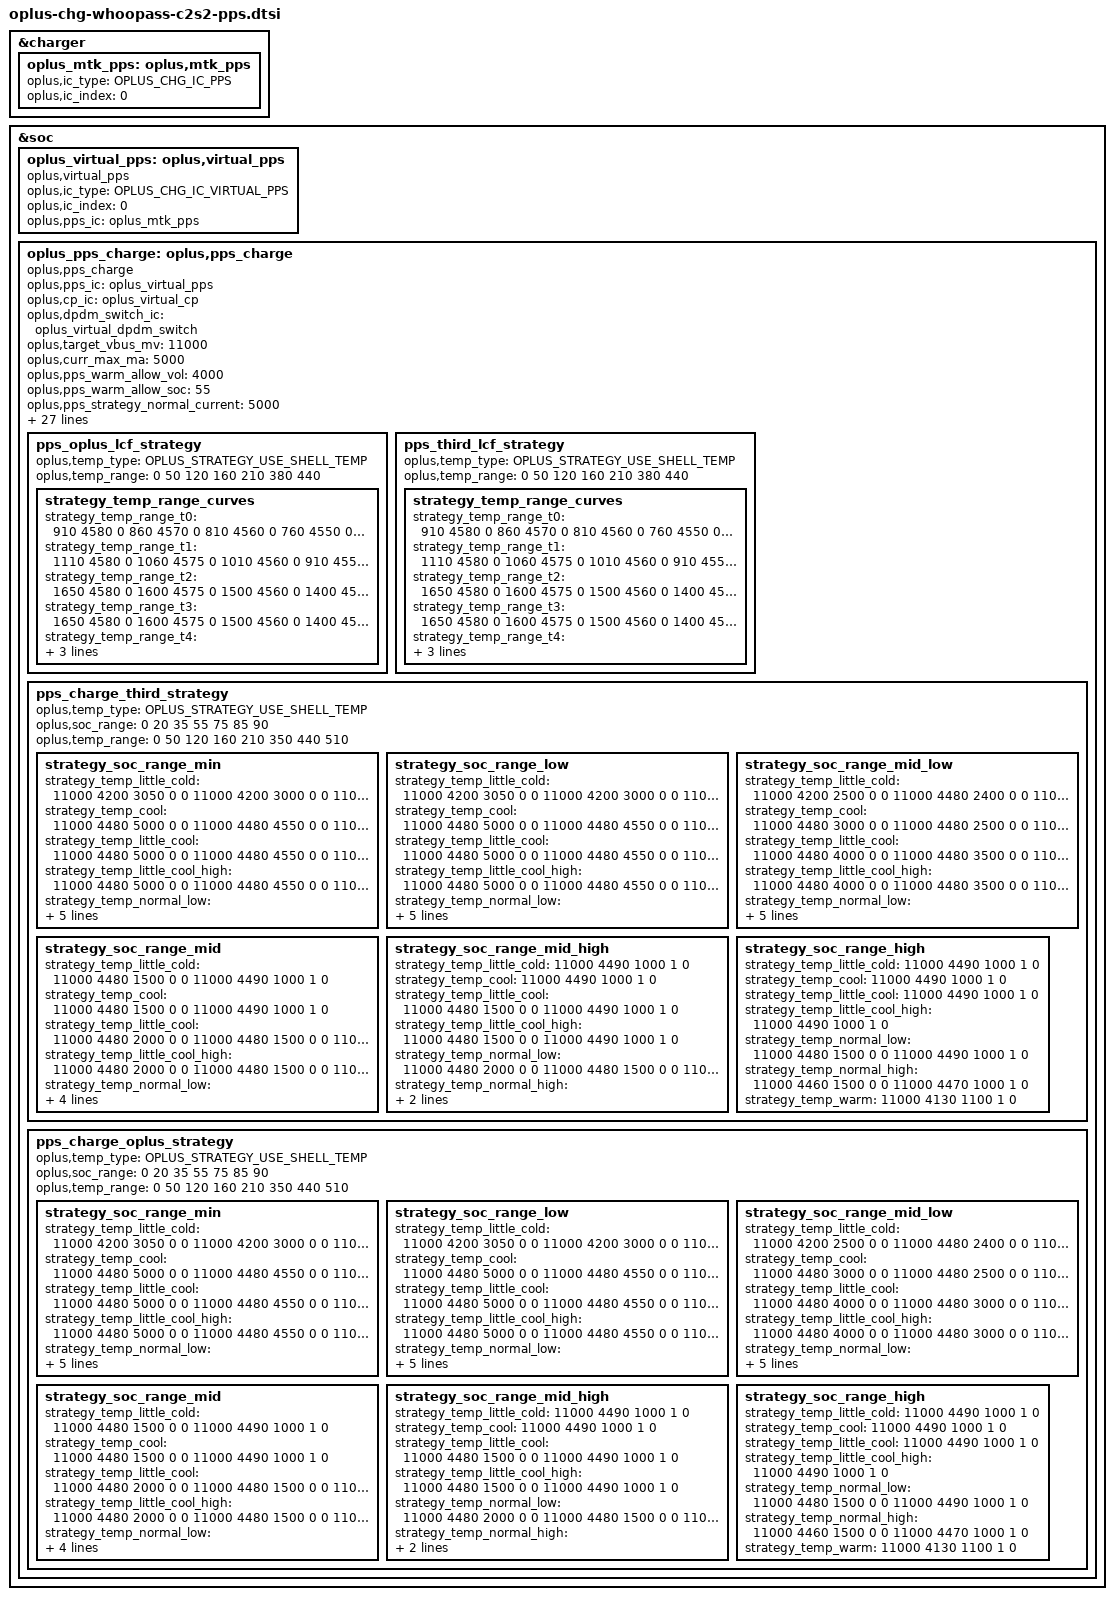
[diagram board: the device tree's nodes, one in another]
//ifdef OPLUS_FEATURE_CHG_BASIC
&charger {
	oplus_mtk_pps: oplus,mtk_pps {
		oplus,ic_type = <OPLUS_CHG_IC_PPS>;
		oplus,ic_index = <0>;
	};
};
&soc {
	oplus_virtual_pps: oplus,virtual_pps {
		compatible = "oplus,virtual_pps";

		oplus,ic_type = <OPLUS_CHG_IC_VIRTUAL_PPS>;
		oplus,ic_index = <0>;
		oplus,pps_ic = <&oplus_mtk_pps>;
	};
	oplus_pps_charge: oplus,pps_charge {
		compatible = "oplus,pps_charge";
		oplus,pps_ic = <&oplus_virtual_pps>;
		oplus,cp_ic = <&oplus_virtual_cp>;
		oplus,dpdm_switch_ic = <&oplus_virtual_dpdm_switch>;

		oplus,target_vbus_mv = <11000>;
		oplus,curr_max_ma = <5000>;

		oplus,pps_warm_allow_vol = <4000>;
		oplus,pps_warm_allow_soc = <55>;
		oplus,pps_strategy_normal_current = <5000>;
		oplus,pps_over_high_or_low_current = <3000>;
		oplus,pps_timeout_third = <15518>;
		oplus,pps_timeout_oplus = <15518>;
		oplus,pps_ibat_over_third = <11400>;
		oplus,pps_ibat_over_oplus = <11400>;
		oplus,pps_full_cool_sw_vbat = <4490>;
		oplus,pps_full_normal_sw_vbat = <4490>;
		oplus,pps_full_normal_hw_vbat = <4540>;
		oplus,pps_full_ffc_vbat = <4540>;
		oplus,pps_full_warm_vbat = <4130>;
		oplus,pps_full_cool_sw_vbat_third = <4490>;
		oplus,pps_full_normal_sw_vbat_third= <4490>;
		oplus,pps_full_normal_hw_vbat_third = <4540>;
		oplus,pps_current_change_timeout = <100>;
		oplus,curve_strategy_name = "pps_ufcs_curve_v2";
		oplus,pps_strategy_batt_high_temp = <410 420 430 400 410 420>;
		oplus,pps_strategy_high_current = <5000 4000 3000 5000 4000 3000>;
		oplus,pps_little_cool_high_temp = <210>;
		oplus,pps_charge_strategy_soc = <0 20 35 55 75 85 90>;
		oplus,pps_charge_strategy_temp = <0 50 120 160 350 440 510>;

		oplus,plc_strategy-data = <&cp_2t1_simple_strategy>;
		oplus,plc_strategy-names = "default";

		pps_oplus_lcf_strategy {
			oplus,temp_type = <OPLUS_STRATEGY_USE_SHELL_TEMP>;
			oplus,temp_range = <0 50 120 160 210 380 440>;

			strategy_temp_range_curves {
				strategy_temp_range_t0 =	<910 4580 0
								 860 4570 0
								 810 4560 0
								 760 4550 0
								 710 4540 1>;
				strategy_temp_range_t1 =	<1110 4580 0
								 1060 4575 0
								 1010 4560 0
								 910 4550 0
								 810 4540 1>;
				strategy_temp_range_t2 =	<1650 4580 0
								 1600 4575 0
								 1500 4560 0
								 1400 4550 0
								 1250 4540 1>;
				strategy_temp_range_t3 =	<1650 4580 0
								 1600 4575 0
								 1500 4560 0
								 1400 4550 0
								 1250 4540 1>;
				strategy_temp_range_t4 =	<2980 4570 0
								 2780 4570 0
								 2230 4570 0
								 1680 4510 0
								 1000 4490 1>;
				strategy_temp_range_t5 =	<3690 4567 0
								 3490 4553 0
								 2690 4520 0
								 1890 4508 0
								 1000 4482 1>;
			};
		};

		pps_third_lcf_strategy {
			oplus,temp_type = <OPLUS_STRATEGY_USE_SHELL_TEMP>;
			oplus,temp_range = <0 50 120 160 210 380 440>;

			strategy_temp_range_curves {
				strategy_temp_range_t0 =	<910 4580 0
								 860 4570 0
								 810 4560 0
								 760 4550 0
								 710 4540 1>;
				strategy_temp_range_t1 =	<1110 4580 0
								 1060 4575 0
								 1010 4560 0
								 910 4550 0
								 810 4540 1>;
				strategy_temp_range_t2 =	<1650 4580 0
								 1600 4575 0
								 1500 4560 0
								 1400 4550 0
								 1250 4540 1>;
				strategy_temp_range_t3 =	<1650 4580 0
								 1600 4575 0
								 1500 4560 0
								 1400 4550 0
								 1250 4540 1>;
				strategy_temp_range_t4 =	<2980 4570 0
								 2780 4570 0
								 2230 4570 0
								 1680 4510 0
								 1000 4490 1>;
				strategy_temp_range_t5 =	<3690 4567 0
								 3490 4553 0
								 2690 4520 0
								 1890 4508 0
								 1000 4482 1>;
			};
		};

		pps_charge_third_strategy {
			oplus,temp_type = <OPLUS_STRATEGY_USE_SHELL_TEMP>;
			oplus,soc_range = <0 20 35 55 75 85 90>;
			oplus,temp_range = <0 50 120 160 210 350 440 510>;

			strategy_soc_range_min {
				strategy_temp_little_cold =	<11000 4200 3050 0 0
								11000 4200 3000 0 0
								11000 4200 2500 0 0
								11000 4480 2400 0 0
								11000 4480 2000 0 0
								11000 4480 1500 0 0
								11000 4490 1000 1 0>;
				strategy_temp_cool =		<11000 4480 5000 0 0
								11000 4480 4550 0 0
								11000 4480 4500 0 0
								11000 4480 4000 0 0
								11000 4480 3500 0 0
								11000 4480 3000 0 0
								11000 4480 2500 0 0
								11000 4480 2000 0 0
								11000 4480 1500 0 0
								11000 4490 1000 1 0>;
				strategy_temp_little_cool =	<11000 4480 5000 0 0
								11000 4480 4550 0 0
								11000 4480 4500 0 0
								11000 4480 4000 0 0
								11000 4480 3500 0 0
								11000 4480 3000 0 0
								11000 4480 2500 0 0
								11000 4480 2000 0 0
								11000 4480 1500 0 0
								11000 4490 1000 1 0>;
				strategy_temp_little_cool_high =	<11000 4480 5000 0 0
								11000 4480 4550 0 0
								11000 4480 4500 0 0
								11000 4480 4000 0 0
								11000 4480 3500 0 0
								11000 4480 3000 0 0
								11000 4480 2500 0 0
								11000 4480 2000 0 0
								11000 4480 1500 0 0
								11000 4490 1000 1 0>;
				strategy_temp_normal_low =	<11000 4480 5000 0 0
								11000 4480 4550 0 0
								11000 4480 4500 0 0
								11000 4480 4000 0 0
								11000 4480 3500 0 0
								11000 4480 3000 0 0
								11000 4480 2500 0 0
								11000 4480 2000 0 0
								11000 4480 1500 0 0
								11000 4490 1000 1 0>;
				strategy_temp_normal_high =	<11000 4460 5000 0 0
								11000 4460 4550 0 0
								11000 4460 4500 0 0
								11000 4460 4000 0 0
								11000 4460 3500 0 0
								11000 4460 3000 0 0
								11000 4460 2500 0 0
								11000 4460 2000 0 0
								11000 4460 1500 0 0
								11000 4470 1000 1 0>;
				strategy_temp_warm =		<11000 4120 1650 0 0
								11000 4120 1500 0 0
								11000 4130 1000 1 0>;
			};
			strategy_soc_range_low {
				strategy_temp_little_cold =	<11000 4200 3050 0 0
								11000 4200 3000 0 0
								11000 4200 2500 0 0
								11000 4480 2400 0 0
								11000 4480 2000 0 0
								11000 4480 1500 0 0
								11000 4490 1000 1 0>;
				strategy_temp_cool =		<11000 4480 5000 0 0
								11000 4480 4550 0 0
								11000 4480 4500 0 0
								11000 4480 4000 0 0
								11000 4480 3500 0 0
								11000 4480 3000 0 0
								11000 4480 2500 0 0
								11000 4480 2000 0 0
								11000 4480 1500 0 0
								11000 4490 1000 1 0>;
				strategy_temp_little_cool =	<11000 4480 5000 0 0
								11000 4480 4550 0 0
								11000 4480 4500 0 0
								11000 4480 4000 0 0
								11000 4480 3500 0 0
								11000 4480 3000 0 0
								11000 4480 2500 0 0
								11000 4480 2000 0 0
								11000 4480 1500 0 0
								11000 4490 1000 1 0>;
				strategy_temp_little_cool_high =	<11000 4480 5000 0 0
								11000 4480 4550 0 0
								11000 4480 4500 0 0
								11000 4480 4000 0 0
								11000 4480 3500 0 0
								11000 4480 3000 0 0
								11000 4480 2500 0 0
								11000 4480 2000 0 0
								11000 4480 1500 0 0
								11000 4490 1000 1 0>;
				strategy_temp_normal_low =	<11000 4480 5000 0 0
								11000 4480 4550 0 0
								11000 4480 4500 0 0
								11000 4480 4000 0 0
								11000 4480 3500 0 0
								11000 4480 3000 0 0
								11000 4480 2500 0 0
								11000 4480 2000 0 0
								11000 4480 1500 0 0
								11000 4490 1000 1 0>;
				strategy_temp_normal_high =	<11000 4460 5000 0 0
								11000 4460 4550 0 0
								11000 4460 4500 0 0
								11000 4460 4000 0 0
								11000 4460 3500 0 0
								11000 4460 3000 0 0
								11000 4460 2500 0 0
								11000 4460 2000 0 0
								11000 4460 1500 0 0
								11000 4470 1000 1 0>;
				strategy_temp_warm =		<11000 4120 1650 0 0
								11000 4120 1500 0 0
								11000 4130 1000 1 0>;
			};
			strategy_soc_range_mid_low {
				strategy_temp_little_cold =	<11000 4200 2500 0 0
								11000 4480 2400 0 0
								11000 4480 2000 0 0
								11000 4480 1500 0 0
								11000 4490 1000 1 0>;
				strategy_temp_cool =		<11000 4480 3000 0 0
								11000 4480 2500 0 0
								11000 4480 2000 0 0
								11000 4480 1500 0 0
								11000 4490 1000 1 0>;
				strategy_temp_little_cool =	<11000 4480 4000 0 0
								11000 4480 3500 0 0
								11000 4480 3000 0 0
								11000 4480 2500 0 0
								11000 4480 2000 0 0
								11000 4480 1500 0 0
								11000 4490 1000 1 0>;
				strategy_temp_little_cool_high =	<11000 4480 4000 0 0
								11000 4480 3500 0 0
								11000 4480 3000 0 0
								11000 4480 2500 0 0
								11000 4480 2000 0 0
								11000 4480 1500 0 0
								11000 4490 1000 1 0>;
				strategy_temp_normal_low =	<11000 4480 5000 0 0
								11000 4480 4550 0 0
								11000 4480 4500 0 0
								11000 4480 4000 0 0
								11000 4480 3500 0 0
								11000 4480 3000 0 0
								11000 4480 2500 0 0
								11000 4480 2000 0 0
								11000 4480 1500 0 0
								11000 4490 1000 1 0>;
				strategy_temp_normal_high =	<11000 4460 5000 0 0
								11000 4460 4550 0 0
								11000 4460 4500 0 0
								11000 4460 4000 0 0
								11000 4460 3500 0 0
								11000 4460 3000 0 0
								11000 4460 2500 0 0
								11000 4460 2000 0 0
								11000 4460 1500 0 0
								11000 4470 1000 1 0>;
				strategy_temp_warm =		<11000 4120 1650 0 0
								11000 4120 1500 0 0
								11000 4130 1000 1 0>;
			};
			strategy_soc_range_mid {
				strategy_temp_little_cold =	<11000 4480 1500 0 0
								11000 4490 1000 1 0>;
				strategy_temp_cool =		<11000 4480 1500 0 0
								11000 4490 1000 1 0>;
				strategy_temp_little_cool =	<11000 4480 2000 0 0
								11000 4480 1500 0 0
								11000 4490 1000 1 0>;
				strategy_temp_little_cool_high =	<11000 4480 2000 0 0
								11000 4480 1500 0 0
								11000 4490 1000 1 0>;
				strategy_temp_normal_low =	<11000 4480 2500 0 0
								11000 4480 2000 0 0
								11000 4480 1500 0 0
								11000 4490 1000 1 0>;
				strategy_temp_normal_high =	<11000 4460 3000 0 0
								11000 4460 2500 0 0
								11000 4460 2000 0 0
								11000 4460 1500 0 0
								11000 4470 1000 1 0>;
				strategy_temp_warm =		<11000 4130 1100 1 0>;
			};
			strategy_soc_range_mid_high {
				strategy_temp_little_cold =	<11000 4490 1000 1 0>;
				strategy_temp_cool =		<11000 4490 1000 1 0>;
				strategy_temp_little_cool =	<11000 4480 1500 0 0
								11000 4490 1000 1 0>;
				strategy_temp_little_cool_high =	<11000 4480 1500 0 0
								11000 4490 1000 1 0>;
				strategy_temp_normal_low =	<11000 4480 2000 0 0
								11000 4480 1500 0 0
								11000 4490 1000 1 0>;
				strategy_temp_normal_high =	<11000 4460 2500 0 0
								11000 4460 2000 0 0
								11000 4460 1500 0 0
								11000 4470 1000 1 0>;
				strategy_temp_warm =		<11000 4130 1100 1 0>;
			};
			strategy_soc_range_high {
				strategy_temp_little_cold =	<11000 4490 1000 1 0>;
				strategy_temp_cool =		<11000 4490 1000 1 0>;
				strategy_temp_little_cool =	<11000 4490 1000 1 0>;
				strategy_temp_little_cool_high =	<11000 4490 1000 1 0>;
				strategy_temp_normal_low =	<11000 4480 1500 0 0
								11000 4490 1000 1 0>;
				strategy_temp_normal_high =	<11000 4460 1500 0 0
								11000 4470 1000 1 0>;
				strategy_temp_warm =		<11000 4130 1100 1 0>;
			};
		};

		pps_charge_oplus_strategy {
			oplus,temp_type = <OPLUS_STRATEGY_USE_SHELL_TEMP>;
			oplus,soc_range = <0 20 35 55 75 85 90>;
			oplus,temp_range = <0 50 120 160 210 350 440 510>;

			strategy_soc_range_min {
				strategy_temp_little_cold =	<11000 4200 3050 0 0
								11000 4200 3000 0 0
								11000 4200 2500 0 0
								11000 4480 2400 0 0
								11000 4480 2000 0 0
								11000 4480 1500 0 0
								11000 4490 1000 1 0>;
				strategy_temp_cool =		<11000 4480 5000 0 0
								11000 4480 4550 0 0
								11000 4480 4500 0 0
								11000 4480 4000 0 0
								11000 4480 3000 0 0
								11000 4480 2500 0 0
								11000 4480 2000 0 0
								11000 4480 1500 0 0
								11000 4490 1000 1 0>;
				strategy_temp_little_cool =	<11000 4480 5000 0 0
								11000 4480 4550 0 0
								11000 4480 4500 0 0
								11000 4480 4000 0 0
								11000 4480 3000 0 0
								11000 4480 2500 0 0
								11000 4480 2000 0 0
								11000 4480 1500 0 0
								11000 4490 1000 1 0>;
				strategy_temp_little_cool_high =	<11000 4480 5000 0 0
								11000 4480 4550 0 0
								11000 4480 4500 0 0
								11000 4480 4000 0 0
								11000 4480 3000 0 0
								11000 4480 2500 0 0
								11000 4480 2000 0 0
								11000 4480 1500 0 0
								11000 4490 1000 1 0>;
				strategy_temp_normal_low =	<11000 4480 5000 0 0
								11000 4480 4550 0 0
								11000 4480 4500 0 0
								11000 4480 4000 0 0
								11000 4480 3000 0 0
								11000 4480 2500 0 0
								11000 4480 2000 0 0
								11000 4480 1500 0 0
								11000 4490 1000 1 0>;
				strategy_temp_normal_high =	<11000 4460 5000 0 0
								11000 4460 4550 0 0
								11000 4460 4500 0 0
								11000 4460 4000 0 0
								11000 4460 3000 0 0
								11000 4460 2500 0 0
								11000 4460 2000 0 0
								11000 4460 1500 0 0
								11000 4470 1000 1 0>;
				strategy_temp_warm =		<11000 4120 1650 0 0
								11000 4120 1500 0 0
								11000 4130 1000 1 0>;
			};
			strategy_soc_range_low {
				strategy_temp_little_cold =	<11000 4200 3050 0 0
								11000 4200 3000 0 0
								11000 4200 2500 0 0
								11000 4480 2400 0 0
								11000 4480 2000 0 0
								11000 4480 1500 0 0
								11000 4490 1000 1 0>;
				strategy_temp_cool =		<11000 4480 5000 0 0
								11000 4480 4550 0 0
								11000 4480 4500 0 0
								11000 4480 4000 0 0
								11000 4480 3000 0 0
								11000 4480 2500 0 0
								11000 4480 2000 0 0
								11000 4480 1500 0 0
								11000 4490 1000 1 0>;
				strategy_temp_little_cool =	<11000 4480 5000 0 0
								11000 4480 4550 0 0
								11000 4480 4500 0 0
								11000 4480 4000 0 0
								11000 4480 3000 0 0
								11000 4480 2500 0 0
								11000 4480 2000 0 0
								11000 4480 1500 0 0
								11000 4490 1000 1 0>;
				strategy_temp_little_cool_high =	<11000 4480 5000 0 0
								11000 4480 4550 0 0
								11000 4480 4500 0 0
								11000 4480 4000 0 0
								11000 4480 3000 0 0
								11000 4480 2500 0 0
								11000 4480 2000 0 0
								11000 4480 1500 0 0
								11000 4490 1000 1 0>;
				strategy_temp_normal_low =	<11000 4480 5000 0 0
								11000 4480 4550 0 0
								11000 4480 4500 0 0
								11000 4480 4000 0 0
								11000 4480 3000 0 0
								11000 4480 2500 0 0
								11000 4480 2000 0 0
								11000 4480 1500 0 0
								11000 4490 1000 1 0>;
				strategy_temp_normal_high =	<11000 4460 5000 0 0
								11000 4460 4550 0 0
								11000 4460 4500 0 0
								11000 4460 4000 0 0
								11000 4460 3000 0 0
								11000 4460 2500 0 0
								11000 4460 2000 0 0
								11000 4460 1500 0 0
								11000 4470 1000 1 0>;
				strategy_temp_warm =		<11000 4120 1650 0 0
								11000 4120 1500 0 0
								11000 4130 1000 1 0>;
			};
			strategy_soc_range_mid_low {
				strategy_temp_little_cold =	<11000 4200 2500 0 0
								11000 4480 2400 0 0
								11000 4480 2000 0 0
								11000 4480 1500 0 0
								11000 4490 1000 1 0>;
				strategy_temp_cool =		<11000 4480 3000 0 0
								11000 4480 2500 0 0
								11000 4480 2000 0 0
								11000 4480 1500 0 0
								11000 4490 1000 1 0>;
				strategy_temp_little_cool =	<11000 4480 4000 0 0
								11000 4480 3000 0 0
								11000 4480 2500 0 0
								11000 4480 2000 0 0
								11000 4480 1500 0 0
								11000 4490 1000 1 0>;
				strategy_temp_little_cool_high =	<11000 4480 4000 0 0
								11000 4480 3000 0 0
								11000 4480 2500 0 0
								11000 4480 2000 0 0
								11000 4480 1500 0 0
								11000 4490 1000 1 0>;
				strategy_temp_normal_low =	<11000 4480 5000 0 0
								11000 4480 4550 0 0
								11000 4480 4500 0 0
								11000 4480 4000 0 0
								11000 4480 3000 0 0
								11000 4480 2500 0 0
								11000 4480 2000 0 0
								11000 4480 1500 0 0
								11000 4490 1000 1 0>;
				strategy_temp_normal_high =	<11000 4460 5000 0 0
								11000 4460 4550 0 0
								11000 4460 4500 0 0
								11000 4460 4000 0 0
								11000 4460 3000 0 0
								11000 4460 2500 0 0
								11000 4460 2000 0 0
								11000 4460 1500 0 0
								11000 4470 1000 1 0>;
				strategy_temp_warm =		<11000 4120 1650 0 0
								11000 4120 1500 0 0
								11000 4130 1000 1 0>;
			};
			strategy_soc_range_mid {
				strategy_temp_little_cold =	<11000 4480 1500 0 0
								11000 4490 1000 1 0>;
				strategy_temp_cool =		<11000 4480 1500 0 0
								11000 4490 1000 1 0>;
				strategy_temp_little_cool =	<11000 4480 2000 0 0
								11000 4480 1500 0 0
								11000 4490 1000 1 0>;
				strategy_temp_little_cool_high =	<11000 4480 2000 0 0
								11000 4480 1500 0 0
								11000 4490 1000 1 0>;
				strategy_temp_normal_low =	<11000 4480 2500 0 0
								11000 4480 2000 0 0
								11000 4480 1500 0 0
								11000 4490 1000 1 0>;
				strategy_temp_normal_high =	<11000 4460 3000 0 0
								11000 4460 2500 0 0
								11000 4460 2000 0 0
								11000 4460 1500 0 0
								11000 4470 1000 1 0>;
				strategy_temp_warm =		<11000 4130 1100 1 0>;
			};
			strategy_soc_range_mid_high {
				strategy_temp_little_cold =	<11000 4490 1000 1 0>;
				strategy_temp_cool =		<11000 4490 1000 1 0>;
				strategy_temp_little_cool =	<11000 4480 1500 0 0
								11000 4490 1000 1 0>;
				strategy_temp_little_cool_high =	<11000 4480 1500 0 0
								11000 4490 1000 1 0>;
				strategy_temp_normal_low =	<11000 4480 2000 0 0
								11000 4480 1500 0 0
								11000 4490 1000 1 0>;
				strategy_temp_normal_high =	<11000 4460 2500 0 0
								11000 4460 2000 0 0
								11000 4460 1500 0 0
								11000 4470 1000 1 0>;
				strategy_temp_warm =		<11000 4130 1100 1 0>;
			};
			strategy_soc_range_high {
				strategy_temp_little_cold =	<11000 4490 1000 1 0>;
				strategy_temp_cool =		<11000 4490 1000 1 0>;
				strategy_temp_little_cool =	<11000 4490 1000 1 0>;
				strategy_temp_little_cool_high =	<11000 4490 1000 1 0>;
				strategy_temp_normal_low =	<11000 4480 1500 0 0
								11000 4490 1000 1 0>;
				strategy_temp_normal_high =	<11000 4460 1500 0 0
								11000 4470 1000 1 0>;
				strategy_temp_warm =		<11000 4130 1100 1 0>;
			};
		};
	};
};
//#endif OPLUS_FEATURE_CHG_BASIC
